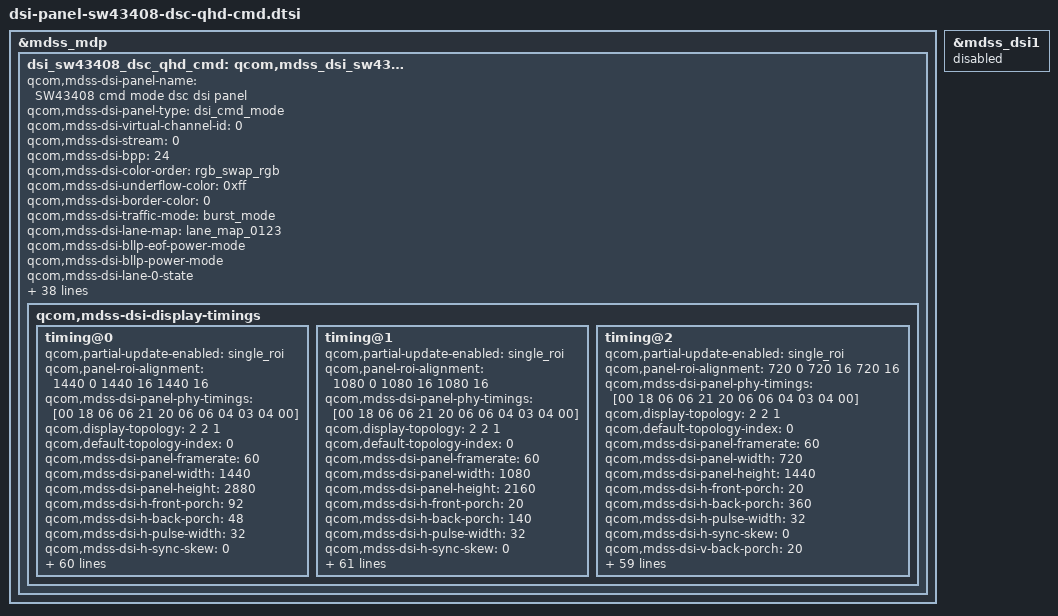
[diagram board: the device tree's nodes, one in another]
/* Copyright (c) 2014, Code Aurora Forum. All rights reserved.
 *
 * This program is free software; you can redistribute it and/or modify
 * it under the terms of the GNU General Public License version 2 and
 * only version 2 as published by the Free Software Foundation.
 *
 * This program is distributed in the hope that it will be useful,
 * but WITHOUT ANY WARRANTY; without even the implied warranty of
 * MERCHANTABILITY or FITNESS FOR A PARTICULAR PURPOSE.  See the
 * GNU General Public License for more details.
 */

&mdss_mdp {
    dsi_sw43408_dsc_qhd_cmd: qcom,mdss_dsi_sw43408_dsc_qhd_cmd {
        qcom,mdss-dsi-panel-name = "SW43408 cmd mode dsc dsi panel";
		qcom,mdss-dsi-panel-type = "dsi_cmd_mode";

		qcom,mdss-dsi-virtual-channel-id = <0>;
		qcom,mdss-dsi-stream = <0>;
		qcom,mdss-dsi-bpp = <24>;
		qcom,mdss-dsi-color-order = "rgb_swap_rgb";
		qcom,mdss-dsi-underflow-color = <0xff>;
		qcom,mdss-dsi-border-color = <0>;
		//qcom,esd-check-enabled;
		//qcom,mdss-dsi-panel-status-check-mode = "te_signal_check";
		qcom,mdss-dsi-traffic-mode = "burst_mode";
		qcom,mdss-dsi-lane-map = "lane_map_0123";
		qcom,mdss-dsi-bllp-eof-power-mode;
		qcom,mdss-dsi-bllp-power-mode;
		qcom,mdss-dsi-lane-0-state;
		qcom,mdss-dsi-lane-1-state;
		qcom,mdss-dsi-lane-2-state;
		qcom,mdss-dsi-lane-3-state;
		qcom,mdss-dsi-reset-sequence = <1 10>, <0 2>, <1 10>;
		qcom,mdss-dsi-dma-trigger = "trigger_sw";
		qcom,mdss-dsi-mdp-trigger = "none";
		qcom,mdss-dsi-te-pin-select = <1>;
		qcom,mdss-dsi-wr-mem-start = <0x2c>;
		qcom,mdss-dsi-wr-mem-continue = <0x3c>;
		qcom,mdss-dsi-te-dcs-command = <1>;
		qcom,mdss-dsi-te-check-enable;
		qcom,mdss-dsi-te-using-te-pin;
		qcom,mdss-dsi-lp11-init;
//		qcom,mdss-dsi-tx-eot-append;
		qcom,mdss-mdp-transfer-time-us = <15000>;
//		qcom,ulps-enabled;
		qcom,mdss-dsi-force-clock-lane-hs = <1>;

		qcom,mdss-dsi-panel-hdr-enabled;
		qcom,mdss-dsi-panel-hdr-color-primaries = <14880 15935 32435 16555 14945 30910 7790 3415>;
		qcom,mdss-dsi-panel-peak-brightness = <5643000>;		/* max. 500nits */
		qcom,mdss-dsi-panel-blackness-level = <6134>;
		qcom,dynamic-mode-switch-enabled;
		qcom,dynamic-mode-switch-type = "dynamic-resolution-switch-immediate";

		lge,aod-interface-data = <0x112>; /* QHD = 1, FHD = 1, HD = 2 */

		lge,blmap = <
			3
			4 4 4 4 4 4 4 4 4 4 4 4 4 4 4 4 4 4 4 4
			4 4 5 5 5 5 5 6 6 7 7 7 8 9 10 10 11 11 12 13
			13 14 14 15 16 17 18 18 19 21 22 23 24 24 25 26 28 29 31 32
			33 35 36 37 38 40 42 43 44 45 47 49 50 51 53 55 57 59 61 62
			64 66 68 71 73 75 76 78 81 83 84 86 88 92 94 95 97 99 101 103
			107 109 112 116 119 122 125 127 129 132 136 138 140 143 148 150 154 156 158 161
			165 169 171 173 177 181 186 189 190 193 197 200 205 209 211 213 218 221 226 228
			230 235 238 242 244 247 250 256 260 262 265 269 275 281 284 288 290 294 299 304
			310 312 315 320 325 330 332 336 341 347 352 355 359 365 370 377 380 382 389 394
			402 406 411 415 419 426 432 439 441 446 453 460 468 471 475 483 489 495 500 504
			515 519 526 535 542 546 550 559 564 570 574 579 586 595 603 607 610 623 626 636
			639 642 652 658 668 670 673 679 688 695 704 710 715 719 726 735 746 750 752 762
			768 777 781 786 795 804 815 818 822 832 841 851 860 870 879 880 890 891 892 893
			894 895 896 897 898 899 900 901 902 903 904 905 906 907 908 909 910 911 912 913
			914 915 916 917 918 919 920 921 922 923 924 925 926 927 928 929 930 931 932 933
			934 935 936 937 938 939 940 941 942 943 944 945 946 947 948 949 950 951 952 953
			954 955 956 957 958 959 960 961 962 963 964 965 966 967 968 969 970 971 972 973
			975 977 979 981 983 985 987 989 991 993 995 997 999 1001 1003 1005 1007 1009 1011 1013
			1015 1017 1019 1021 1023
		>;
		lge,blmap-ex = <
			3
			1023 1023 1023 1023 1023 1023 1023 1023 1023 1023 1023 1023 1023 1023 1023 1023 1023 1023 1023 1023
			1023 1023 1023 1023 1023 1023 1023 1023 1023 1023 1023 1023 1023 1023 1023 1023 1023 1023 1023 1023
			1023 1023 1023 1023 1023 1023 1023 1023 1023 1023 1023 1023 1023 1023 1023 1023 1023 1023 1023 1023
			1023 1023 1023 1023 1023 1023 1023 1023 1023 1023 1023 1023 1023 1023 1023 1023 1023 1023 1023 1023
			1023 1023 1023 1023 1023 1023 1023 1023 1023 1023 1023 1023 1023 1023 1023 1023 1023 1023 1023 1023
			1023 1023 1023 1023 1023 1023 1023 1023 1023 1023 1023 1023 1023 1023 1023 1023 1023 1023 1023 1023
			1023 1023 1023 1023 1023 1023 1023 1023 1023 1023 1023 1023 1023 1023 1023 1023 1023 1023 1023 1023
			1023 1023 1023 1023 1023 1023 1023 1023 1023 1023 1023 1023 1023 1023 1023 1023 1023 1023 1023 1023
			1023 1023 1023 1023 1023 1023 1023 1023 1023 1023 1023 1023 1023 1023 1023 1023 1023 1023 1023 1023
			1023 1023 1023 1023 1023 1023 1023 1023 1023 1023 1023 1023 1023 1023 1023 1023 1023 1023 1023 1023
			1023 1023 1023 1023 1023 1023 1023 1023 1023 1023 1023 1023 1023 1023 1023 1023 1023 1023 1023 1023
			1023 1023 1023 1023 1023 1023 1023 1023 1023 1023 1023 1023 1023 1023 1023 1023 1023 1023 1023 1023
			1023 1023 1023 1023 1023 1023 1023 1023 1023 1023 1023 1023 1023 1023 1023
		>;

		qcom,mdss-pan-physical-width-dimension = <68>;
		qcom,mdss-pan-physical-height-dimension = <136>;

		qcom,mdss-dsi-t-clk-post = <0x0C>;
		qcom,mdss-dsi-t-clk-pre = <0x27>;

		lge,mdss-dsi-nolp-command = [
			39 01 00 00 00 00 03 53 0C 30
			39 01 00 00 12 00 03 51 00 00
			05 01 00 00 00 00 01 22
			15 01 00 00 00 00 02 B0 AC
			39 01 00 00 00 00 05 CB 80 5C 07 11
			05 01 00 00 40 00 01 28
			05 01 00 00 00 00 01 13
			05 01 00 00 00 00 01 29
		];
		lge,mdss-dsi-nolp-command-state = "dsi_lp_mode";

		lge,mdss-dsi-lp2-command = [
			05 01 00 00 00 00 01 22
			15 01 00 00 00 00 02 B0 AC
			39 01 00 00 54 00 05 CB 80 5C 07 07
			39 01 00 00 00 00 03 53 4C 30
			05 01 00 00 00 00 01 12
		];
		lge,mdss-dsi-lp2-command-state = "dsi_lp_mode";

		qcom,mdss-dsi-display-timings {
			timing@0{
				qcom,partial-update-enabled = "single_roi";
				qcom,panel-roi-alignment = <1440 0 1440 16 1440 16>;
				qcom,mdss-dsi-panel-phy-timings = [00 18 06 06 21 20 06 06 04 03 04 00];
				qcom,display-topology = <2 2 1>;
				qcom,default-topology-index = <0>;
				qcom,mdss-dsi-panel-framerate = <60>;
				qcom,mdss-dsi-panel-width = <1440>;
				qcom,mdss-dsi-panel-height = <2880>;
				qcom,mdss-dsi-h-front-porch = <92>;
				qcom,mdss-dsi-h-back-porch = <48>;
				qcom,mdss-dsi-h-pulse-width = <32>;
				qcom,mdss-dsi-h-sync-skew = <0>;
				qcom,mdss-dsi-v-back-porch = <25>;
				qcom,mdss-dsi-v-front-porch = <10>;
				qcom,mdss-dsi-v-pulse-width = <1>;
				qcom,mdss-dsi-h-left-border = <0>;
				qcom,mdss-dsi-h-right-border = <0>;
				qcom,mdss-dsi-v-top-border = <0>;
				qcom,mdss-dsi-v-bottom-border = <0>;
				qcom,mdss-dsi-on-command = [
					15 01 00 00 00 00 02 B0 AC
					15 01 00 00 00 00 02 3D 00
					15 01 00 00 00 00 02 F3 AC
					39 01 00 00 00 00 05 CE 27 10 08 80
					05 01 00 00 14 00 01 11
					15 01 00 00 00 00 02 B0 AC
					07 01 00 00 00 00 01 11
					15 01 00 00 00 00 02 26 02
					39 01 00 00 00 00 03 53 0C 30
					39 01 00 00 00 00 07 55 04 70 DB 00 78 DB
					05 01 00 00 A0 00 01 35
					];
				qcom,mdss-dsi-on-command-state = "dsi_hs_mode";

				qcom,mdss-dsi-post-panel-on-command = [
					05 01 00 00 00 00 01 29
				];

				qcom,mdss-dsi-off-command = [
					39 01 00 00 00 00 05 CA 08 98 18 05
					05 01 00 00 00 00 01 28
					05 01 00 00 96 00 01 10
					];
				qcom,mdss-dsi-off-command-state = "dsi_hs_mode";

				qcom,mdss-dsi-timing-switch-command = [
					15 01 00 00 00 00 02 B0 AC
					15 01 00 00 00 00 02 3D 00
				];
				qcom,mdss-dsi-timing-switch-command-state = "dsi_lp_mode";

				lge,mdss-dsi-color-manager-mode-table = <3 1>, <0 1>, <2 1>, <1 1>;

				lge,mdss-dsi-disp-ctrl-command-1 = [
					15 01 00 00 00 00 03 53 0C 30
				];
				lge,mdss-dsi-disp-ctrl-command-1-state = "dsi_hs_mode";
				lge,mdss-dsi-disp-ctrl-command-2 = [
					15 01 00 00 00 00 07 55 04 70 DB 00 78 DB
				];
				lge,mdss-dsi-disp-ctrl-command-2-state = "dsi_hs_mode";

				lge,mdss-dsi-wb-default-command = [
					39 01 00 00 00 00 0A CF 00 00 00 00 00 00 00 00 00
				     39 01 00 00 00 00 1C D0 00 00 00 00 00 00 00 00 00 00 00 00 00 00 00 00 00 00 00 00 00 00 00 00 00 00 00
				];
				lge,mdss-dsi-cm-dci-p3-command = [
					39 01 00 00 00 00 1D D6 70 5C 5C 58 22 14 F0 DA A2 DC 0A 16 24 04 F5 00 7C 7A 76 72 78 4B 46 56 78 68 64 64
				];
				lge,mdss-dsi-cm-dci-p3-command-state = "dsi_hs_mode";

				lge,mdss-dsi-cm-srgb-command = [
					39 01 00 00 00 00 1D D7 70 55 4F 4E 2D 0D E8 D7 8C 80 1E 37 19 FA DC 14 66 5F 5E 57 57 30 31 57 78 64 50 50
				];
				lge,mdss-dsi-cm-srgb-command-state = "dsi_hs_mode";

				lge,mdss-dsi-cm-adobe-command = [
					39 01 00 00 00 00 1D D8 70 62 5C 58 34 04 E4 1E 3C 19 0F FE 24 0A 0D 23 6E 68 69 63 7D 78 6E 68 74 57 4B 55
				];
				lge,mdss-dsi-cm-adobe-command-state = "dsi_hs_mode";

				lge,mdss-dsi-cm-native-command = [
					39 01 00 00 00 00 1D D9 70 55 78 70 08 07 F0 FA 00 FA 0A 00 00 00 00 0A 80 7C 80 78 78 7C 71 80 80 80 78 78
				];
				lge,mdss-dsi-cm-native-command-state = "dsi_hs_mode";

				lge,digital-gamma-cmds-dummy = [
					39 00 00 00 00 00 0A CF 00 00 00 00 00 00 00 00 00
					39 01 00 00 00 00 1C D0 00 00 00 00 00 00 00 00 00 00 00 00 00 00 00 00 00 00 00 00 00 00 00 00 00 00 00
				];

				qcom,mdss-dsi-h-sync-pulse = <0>;
				qcom,compression-mode = "dsc";
				qcom,mdss-dsc-slice-height = <16>;
				qcom,mdss-dsc-slice-width = <720>;
				qcom,mdss-dsc-slice-per-pkt = <2>;
				qcom,mdss-dsc-bit-per-component = <8>;
				qcom,mdss-dsc-bit-per-pixel = <8>;
				qcom,lm-split = <720 720>;
				qcom,mdss-dsc-encoders = <2>;
				qcom,mdss-dsc-block-prediction-enable;
				qcom,mdss-dsi-pps-command-state = "dsi_hs_mode";
			};

			timing@1 {
				qcom,partial-update-enabled = "single_roi";
				qcom,panel-roi-alignment = <1080 0 1080 16 1080 16>;
				qcom,mdss-dsi-panel-phy-timings = [00 18 06 06 21 20 06 06 04 03 04 00];
				qcom,display-topology = <2 2 1>;
				qcom,default-topology-index = <0>;
				qcom,mdss-dsi-panel-framerate = <60>;
				qcom,mdss-dsi-panel-width = <1080>;
				qcom,mdss-dsi-panel-height = <2160>;
				qcom,mdss-dsi-h-front-porch = <20>;
				qcom,mdss-dsi-h-back-porch = <140>;
				qcom,mdss-dsi-h-pulse-width = <32>;
				qcom,mdss-dsi-h-sync-skew = <0>;
				qcom,mdss-dsi-v-back-porch = <20>;
				qcom,mdss-dsi-v-front-porch = <740>;
				qcom,mdss-dsi-v-pulse-width = <6>;
				qcom,mdss-dsi-h-left-border = <0>;
				qcom,mdss-dsi-h-right-border = <0>;
				qcom,mdss-dsi-v-top-border = <0>;
				qcom,mdss-dsi-v-bottom-border = <0>;

				lge,mdss-dsi-color-manager-mode-table = <3 1>, <0 1>, <2 1>, <1 1>;

				lge,mdss-dsi-disp-ctrl-command-1 = [
					15 01 00 00 00 00 03 53 0C 30
				];
				lge,mdss-dsi-disp-ctrl-command-1-state = "dsi_hs_mode";
				lge,mdss-dsi-disp-ctrl-command-2 = [
					15 01 00 00 00 00 07 55 04 70 DB 00 78 DB
				];
				lge,mdss-dsi-disp-ctrl-command-2-state = "dsi_hs_mode";

				lge,mdss-dsi-wb-default-command = [
					39 01 00 00 00 00 0A CF 00 00 00 00 00 00 00 00 00
				     39 01 00 00 00 00 1C D0 00 00 00 00 00 00 00 00 00 00 00 00 00 00 00 00 00 00 00 00 00 00 00 00 00 00 00
				];
				lge,mdss-dsi-cm-dci-p3-command = [
					39 01 00 00 00 00 1D D6 70 5C 5C 58 22 14 F0 DA A2 DC 0A 16 24 04 F5 00 7C 7A 76 72 78 4B 46 56 78 68 64 64
				];
				lge,mdss-dsi-cm-dci-p3-command-state = "dsi_hs_mode";

				lge,mdss-dsi-cm-srgb-command = [
					39 01 00 00 00 00 1D D7 70 55 4F 4E 2D 0D E8 D7 8C 80 1E 37 19 FA DC 14 66 5F 5E 57 57 30 31 57 78 64 50 50
				];
				lge,mdss-dsi-cm-srgb-command-state = "dsi_hs_mode";

				lge,mdss-dsi-cm-adobe-command = [
					39 01 00 00 00 00 1D D8 70 62 5C 58 34 04 E4 1E 3C 19 0F FE 24 0A 0D 23 6E 68 69 63 7D 78 6E 68 74 57 4B 55
				];
				lge,mdss-dsi-cm-adobe-command-state = "dsi_hs_mode";

				lge,mdss-dsi-cm-native-command = [
					39 01 00 00 00 00 1D D9 70 55 78 70 08 07 F0 FA 00 FA 0A 00 00 00 00 0A 80 7C 80 78 78 7C 71 80 80 80 78 78
				];
				lge,mdss-dsi-cm-native-command-state = "dsi_hs_mode";

				lge,digital-gamma-cmds-dummy = [
					39 00 00 00 00 00 0A CF 00 00 00 00 00 00 00 00 00
					39 01 00 00 00 00 1C D0 00 00 00 00 00 00 00 00 00 00 00 00 00 00 00 00 00 00 00 00 00 00 00 00 00 00 00
				];

				qcom,mdss-dsi-on-command = [
					15 01 00 00 00 00 02 B0 AC
					15 01 00 00 00 00 02 3D 01
					15 01 00 00 00 00 02 F3 AC
					39 01 00 00 00 00 05 CE 27 10 08 80
					05 01 00 00 14 00 01 11
					15 01 00 00 00 00 02 B0 AC
					07 01 00 00 00 00 01 11
					15 01 00 00 00 00 02 26 02
					39 01 00 00 00 00 03 51 03 6F
					39 01 00 00 00 00 03 53 0C 30
					39 01 00 00 00 00 07 55 04 70 DB 00 78 DB
					05 01 00 00 A0 00 01 35
				];
				qcom,mdss-dsi-on-command-state = "dsi_lp_mode";

				qcom,mdss-dsi-post-panel-on-command = [
					05 01 00 00 00 00 01 29
				];

				qcom,mdss-dsi-off-command = [
					05 01 00 00 00 00 01 28
					05 01 00 00 5A 00 01 10
				];
				qcom,mdss-dsi-timing-switch-command = [
					15 01 00 00 00 00 02 B0 AC
					15 01 00 00 00 00 02 3D 01
				];

				qcom,mdss-dsi-timing-switch-command-state = "dsi_lp_mode";
				qcom,mdss-dsi-off-command-state = "dsi_lp_mode";
				qcom,compression-mode = "dsc";
				qcom,mdss-dsc-version = <0x11>;
				qcom,mdss-dsc-scr-version = <0x1>;
				qcom,mdss-dsc-slice-height = <16>;
				qcom,mdss-dsc-slice-width = <540>;
				qcom,mdss-dsc-slice-per-pkt = <2>;
				qcom,mdss-dsc-bit-per-component = <8>;
				qcom,mdss-dsc-bit-per-pixel = <8>;
				qcom,lm-split = <540 540>;
				qcom,mdss-dsc-encoders = <2>;
				qcom,mdss-dsc-block-prediction-enable;
 				qcom,mdss-dsi-pps-command-state = "dsi_hs_mode";
			};

			timing@2{
				qcom,partial-update-enabled = "single_roi";
				qcom,panel-roi-alignment = <720 0 720 16 720 16>;
				qcom,mdss-dsi-panel-phy-timings = [00 18 06 06 21 20 06 06 04 03 04 00];
				qcom,display-topology = <2 2 1>;
				qcom,default-topology-index = <0>;
				qcom,mdss-dsi-panel-framerate = <60>;
				qcom,mdss-dsi-panel-width = <720>;
				qcom,mdss-dsi-panel-height = <1440>;
				qcom,mdss-dsi-h-front-porch = <20>;
				qcom,mdss-dsi-h-back-porch = <360>;
				qcom,mdss-dsi-h-pulse-width = <32>;
				qcom,mdss-dsi-h-sync-skew = <0>;
				qcom,mdss-dsi-v-back-porch = <20>;
				qcom,mdss-dsi-v-front-porch = <1460>;
				qcom,mdss-dsi-v-pulse-width = <6>;
				qcom,mdss-dsi-h-left-border = <0>;
				qcom,mdss-dsi-h-right-border = <0>;
				qcom,mdss-dsi-v-top-border = <0>;
				qcom,mdss-dsi-v-bottom-border = <0>;

				lge,mdss-dsi-color-manager-mode-table = <3 1>, <0 1>, <2 1>, <1 1>;

				lge,mdss-dsi-disp-ctrl-command-1 = [
					15 01 00 00 00 00 03 53 0C 30
				];
				lge,mdss-dsi-disp-ctrl-command-1-state = "dsi_hs_mode";
				lge,mdss-dsi-disp-ctrl-command-2 = [
					15 01 00 00 00 00 07 55 04 70 DB 00 78 DB
				];
				lge,mdss-dsi-disp-ctrl-command-2-state = "dsi_hs_mode";

				lge,mdss-dsi-wb-default-command = [
					39 01 00 00 00 00 0A CF 00 00 00 00 00 00 00 00 00
				     39 01 00 00 00 00 1C D0 00 00 00 00 00 00 00 00 00 00 00 00 00 00 00 00 00 00 00 00 00 00 00 00 00 00 00
				];
				lge,mdss-dsi-cm-dci-p3-command = [
					39 01 00 00 00 00 1D D6 70 5C 5C 58 22 14 F0 DA A2 DC 0A 16 24 04 F5 00 7C 7A 76 72 78 4B 46 56 78 68 64 64
				];
				lge,mdss-dsi-cm-dci-p3-command-state = "dsi_hs_mode";

				lge,mdss-dsi-cm-srgb-command = [
					39 01 00 00 00 00 1D D7 70 55 4F 4E 2D 0D E8 D7 8C 80 1E 37 19 FA DC 14 66 5F 5E 57 57 30 31 57 78 64 50 50
				];
				lge,mdss-dsi-cm-srgb-command-state = "dsi_hs_mode";

				lge,mdss-dsi-cm-adobe-command = [
					39 01 00 00 00 00 1D D8 70 62 5C 58 34 04 E4 1E 3C 19 0F FE 24 0A 0D 23 6E 68 69 63 7D 78 6E 68 74 57 4B 55
				];
				lge,mdss-dsi-cm-adobe-command-state = "dsi_hs_mode";

				lge,mdss-dsi-cm-native-command = [
					39 01 00 00 00 00 1D D9 70 55 78 70 08 07 F0 FA 00 FA 0A 00 00 00 00 0A 80 7C 80 78 78 7C 71 80 80 80 78 78
				];
				lge,mdss-dsi-cm-native-command-state = "dsi_hs_mode";

				lge,digital-gamma-cmds-dummy = [
					39 00 00 00 00 00 0A CF 00 00 00 00 00 00 00 00 00
					39 01 00 00 00 00 1C D0 00 00 00 00 00 00 00 00 00 00 00 00 00 00 00 00 00 00 00 00 00 00 00 00 00 00 00
				];

				qcom,mdss-dsi-on-command = [
					15 01 00 00 00 00 02 B0 AC
					15 01 00 00 00 00 02 3D 03
					15 01 00 00 00 00 02 F3 AC
					39 01 00 00 00 00 05 CE 27 10 08 80
					05 01 00 00 14 00 01 11
					15 01 00 00 00 00 02 B0 AC
					07 01 00 00 00 00 01 11
					15 01 00 00 00 00 02 26 02
					39 01 00 00 00 00 03 51 03 6F
					39 01 00 00 00 00 03 53 0C 30
					39 01 00 00 00 00 07 55 04 70 DB 00 78 DB
					05 01 00 00 A0 00 01 35
				];
				qcom,mdss-dsi-on-command-state = "dsi_lp_mode";

				qcom,mdss-dsi-post-panel-on-command = [
					05 01 00 00 00 00 01 29
				];

				qcom,mdss-dsi-off-command = [
					05 01 00 00 00 00 01 28
					05 01 00 00 5A 00 01 10
				];
				qcom,mdss-dsi-timing-switch-command = [
					15 01 00 00 00 00 02 B0 AC
					15 01 00 00 00 00 02 3D 03
				];
				qcom,mdss-dsi-timing-switch-command-state = "dsi_lp_mode";

				qcom,compression-mode = "dsc";
				qcom,mdss-dsc-version = <0x11>;
				qcom,mdss-dsc-scr-version = <0x1>;
				qcom,mdss-dsc-slice-height = <16>;
				qcom,mdss-dsc-slice-width = <360>;
				qcom,mdss-dsc-slice-per-pkt = <2>;
				qcom,mdss-dsc-bit-per-component = <8>;
				qcom,mdss-dsc-bit-per-pixel = <8>;
				qcom,lm-split = <360 360>;
				qcom,mdss-dsc-encoders = <2>;
				qcom,mdss-dsc-block-prediction-enable;
				qcom,mdss-dsi-pps-command-state = "dsi_hs_mode";
			};
		};
	};
};
/*
&spmi_bus {
	qcom,pmi8998@3 {
		labibb: qpnp-labibb-regulator {
			status = "disabled";
		};
	};
};
*/
&mdss_dsi1 {
	status = "disabled";
};
